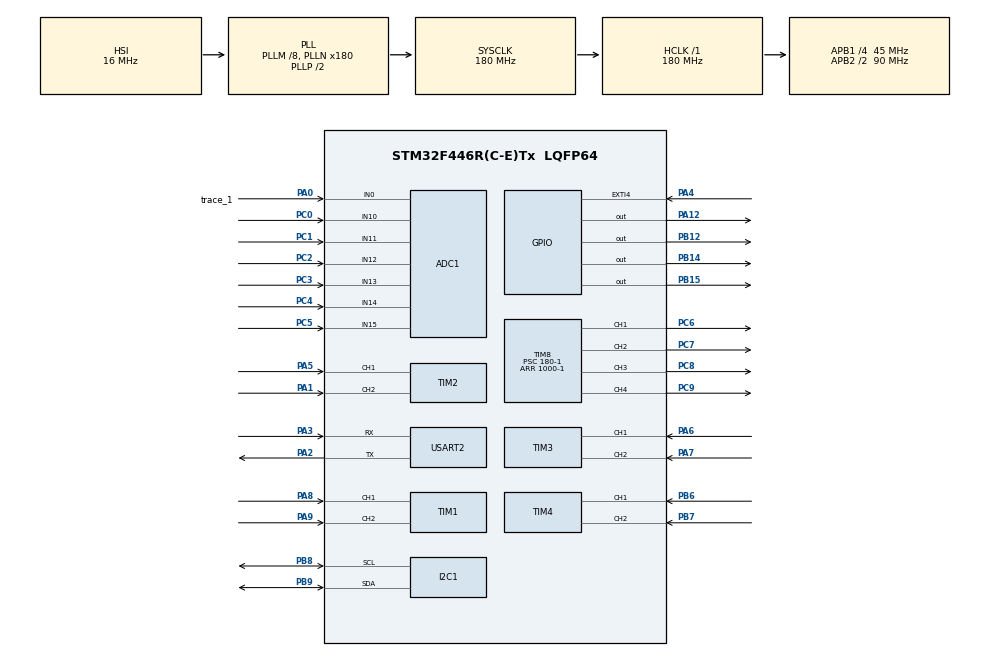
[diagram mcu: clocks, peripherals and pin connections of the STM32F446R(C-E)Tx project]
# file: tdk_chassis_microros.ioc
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ADC1.Channel-0\#ChannelRegularConversion=ADC_CHANNEL_0
ADC1.Channel-1\#ChannelRegularConversion=ADC_CHANNEL_10
ADC1.Channel-2\#ChannelRegularConversion=ADC_CHANNEL_11
ADC1.Channel-3\#ChannelRegularConversion=ADC_CHANNEL_12
ADC1.Channel-4\#ChannelRegularConversion=ADC_CHANNEL_13
ADC1.Channel-5\#ChannelRegularConversion=ADC_CHANNEL_14
ADC1.Channel-6\#ChannelRegularConversion=ADC_CHANNEL_15
ADC1.ContinuousConvMode=ENABLE
ADC1.DMAContinuousRequests=ENABLE
ADC1.DiscontinuousConvMode=DISABLE
ADC1.NbrOfConversion=7
ADC1.NbrOfConversionFlag=1
ADC1.Rank-0\#ChannelRegularConversion=1
ADC1.Rank-1\#ChannelRegularConversion=2
ADC1.Rank-2\#ChannelRegularConversion=3
ADC1.Rank-3\#ChannelRegularConversion=4
ADC1.Rank-4\#ChannelRegularConversion=5
ADC1.Rank-5\#ChannelRegularConversion=6
ADC1.Rank-6\#ChannelRegularConversion=7
ADC1.SamplingTime-0\#ChannelRegularConversion=ADC_SAMPLETIME_15CYCLES
ADC1.SamplingTime-1\#ChannelRegularConversion=ADC_SAMPLETIME_15CYCLES
ADC1.SamplingTime-2\#ChannelRegularConversion=ADC_SAMPLETIME_15CYCLES
ADC1.SamplingTime-3\#ChannelRegularConversion=ADC_SAMPLETIME_15CYCLES
ADC1.SamplingTime-4\#ChannelRegularConversion=ADC_SAMPLETIME_15CYCLES
ADC1.SamplingTime-5\#ChannelRegularConversion=ADC_SAMPLETIME_15CYCLES
ADC1.SamplingTime-6\#ChannelRegularConversion=ADC_SAMPLETIME_15CYCLES
ADC1.ScanConvMode=ENABLE
ADC1.master=1
Dma.ADC1.2.Direction=DMA_PERIPH_TO_MEMORY
Dma.ADC1.2.FIFOMode=DMA_FIFOMODE_DISABLE
Dma.ADC1.2.Instance=DMA2_Stream0
Dma.ADC1.2.MemDataAlignment=DMA_MDATAALIGN_HALFWORD
Dma.ADC1.2.MemInc=DMA_MINC_ENABLE
Dma.ADC1.2.Mode=DMA_CIRCULAR
Dma.ADC1.2.PeriphDataAlignment=DMA_PDATAALIGN_HALFWORD
Dma.ADC1.2.PeriphInc=DMA_PINC_DISABLE
Dma.ADC1.2.Priority=DMA_PRIORITY_LOW
Dma.Request0=USART2_RX
Dma.Request1=USART2_TX
Dma.Request2=ADC1
Dma.USART2_RX.0.Direction=DMA_PERIPH_TO_MEMORY
Dma.USART2_RX.0.FIFOMode=DMA_FIFOMODE_DISABLE
Dma.USART2_RX.0.Instance=DMA1_Stream5
Dma.USART2_RX.0.MemDataAlignment=DMA_MDATAALIGN_BYTE
Dma.USART2_RX.0.MemInc=DMA_MINC_ENABLE
Dma.USART2_RX.0.Mode=DMA_CIRCULAR
Dma.USART2_RX.0.PeriphDataAlignment=DMA_PDATAALIGN_BYTE
Dma.USART2_RX.0.PeriphInc=DMA_PINC_DISABLE
Dma.USART2_RX.0.Priority=DMA_PRIORITY_VERY_HIGH
Dma.USART2_TX.1.Direction=DMA_MEMORY_TO_PERIPH
Dma.USART2_TX.1.FIFOMode=DMA_FIFOMODE_DISABLE
Dma.USART2_TX.1.Instance=DMA1_Stream6
Dma.USART2_TX.1.MemDataAlignment=DMA_MDATAALIGN_BYTE
Dma.USART2_TX.1.MemInc=DMA_MINC_ENABLE
Dma.USART2_TX.1.Mode=DMA_NORMAL
Dma.USART2_TX.1.PeriphDataAlignment=DMA_PDATAALIGN_BYTE
Dma.USART2_TX.1.PeriphInc=DMA_PINC_DISABLE
Dma.USART2_TX.1.Priority=DMA_PRIORITY_VERY_HIGH
FREERTOS.Tasks01=defaultTask,24,3000,StartDefaultTask,Default,NULL,Static,defaultTaskBuffer,defaultTaskControlBlock
FREERTOS.configUSE_NEWLIB_REENTRANT=1
Mcu.Family=STM32F4
Mcu.Name=STM32F446R(C-E)Tx
Mcu.Package=LQFP64
NVIC.DMA1_Stream5_IRQn=true\:5\:0\:false\:false\:true\:true\:false\:true\:true
NVIC.DMA1_Stream6_IRQn=true\:5\:0\:false\:false\:true\:true\:false\:true\:true
NVIC.DMA2_Stream0_IRQn=true\:5\:0\:false\:false\:true\:true\:false\:true\:true
NVIC.EXTI4_IRQn=true\:5\:0\:false\:false\:true\:true\:true\:true\:true
NVIC.PriorityGroup=NVIC_PRIORITYGROUP_4
NVIC.TIM5_IRQn=true\:5\:0\:false\:false\:true\:true\:true\:true\:true
NVIC.TIM6_DAC_IRQn=true\:15\:0\:false\:false\:true\:false\:false\:true\:true
NVIC.TimeBase=TIM6_DAC_IRQn
NVIC.TimeBaseIP=TIM6
NVIC.USART2_IRQn=true\:5\:0\:false\:false\:true\:true\:true\:true\:true
PA0-WKUP.GPIO_Label=trace_1
PA0-WKUP.Signal=ADCx_IN0
PA1.Signal=S_TIM2_CH2
PA12.Signal=GPIO_Output
PA13.Mode=Serial_Wire
PA13.Signal=SYS_JTMS-SWDIO
PA14.Mode=Serial_Wire
PA14.Signal=SYS_JTCK-SWCLK
PA2.Mode=Asynchronous
PA2.Signal=USART2_TX
PA3.Mode=Asynchronous
PA3.Signal=USART2_RX
PA4.GPIO_ModeDefaultEXTI=GPIO_MODE_IT_FALLING
PA4.GPIO_PuPd=GPIO_PULLUP
PA4.Signal=GPXTI4
PA5.Signal=S_TIM2_CH1_ETR
PA6.Signal=S_TIM3_CH1
PA7.Signal=S_TIM3_CH2
PA8.Signal=S_TIM1_CH1
PA9.Signal=S_TIM1_CH2
PB12.Signal=GPIO_Output
PB14.Signal=GPIO_Output
PB15.Signal=GPIO_Output
PB6.Signal=S_TIM4_CH1
PB7.Signal=S_TIM4_CH2
PB8.Mode=I2C
PB8.Signal=I2C1_SCL
PB9.Mode=I2C
PB9.Signal=I2C1_SDA
PC0.Signal=ADCx_IN10
PC1.Signal=ADCx_IN11
PC2.Signal=ADCx_IN12
PC3.Signal=ADCx_IN13
PC4.Signal=ADCx_IN14
PC5.Signal=ADCx_IN15
PC6.Signal=S_TIM8_CH1
PC7.Signal=S_TIM8_CH2
PC8.Signal=S_TIM8_CH3
PC9.Signal=S_TIM8_CH4
ProjectManager.HeapSize=0x200
ProjectManager.StackSize=0x400
ProjectManager.TargetToolchain=STM32CubeIDE
RCC.AHBFreq_Value=180000000
RCC.APB1CLKDivider=RCC_HCLK_DIV4
RCC.APB1Freq_Value=45000000
RCC.APB1TimFreq_Value=90000000
RCC.APB2CLKDivider=RCC_HCLK_DIV2
RCC.APB2Freq_Value=90000000
RCC.APB2TimFreq_Value=180000000
RCC.CortexFreq_Value=180000000
RCC.HCLKFreq_Value=180000000
RCC.PLLM=8
RCC.PLLN=180
RCC.SYSCLKFreq_VALUE=180000000
RCC.SYSCLKSource=RCC_SYSCLKSOURCE_PLLCLK
RCC.USBFreq_Value=180000000
RCC.VCOOutputFreq_Value=360000000
SH.ADCx_IN0.0=ADC1_IN0,IN0
SH.ADCx_IN10.0=ADC1_IN10,IN10
SH.ADCx_IN11.0=ADC1_IN11,IN11
SH.ADCx_IN12.0=ADC1_IN12,IN12
SH.ADCx_IN13.0=ADC1_IN13,IN13
SH.ADCx_IN14.0=ADC1_IN14,IN14
SH.ADCx_IN15.0=ADC1_IN15,IN15
SH.S_TIM1_CH1.0=TIM1_CH1,Encoder_Interface
SH.S_TIM1_CH2.0=TIM1_CH2,Encoder_Interface
SH.S_TIM2_CH1_ETR.0=TIM2_CH1,Encoder_Interface
SH.S_TIM2_CH2.0=TIM2_CH2,Encoder_Interface
SH.S_TIM3_CH1.0=TIM3_CH1,Encoder_Interface
SH.S_TIM3_CH2.0=TIM3_CH2,Encoder_Interface
SH.S_TIM4_CH1.0=TIM4_CH1,Encoder_Interface
SH.S_TIM4_CH2.0=TIM4_CH2,Encoder_Interface
SH.S_TIM8_CH1.0=TIM8_CH1,PWM Generation1 CH1
SH.S_TIM8_CH2.0=TIM8_CH2,PWM Generation2 CH2
SH.S_TIM8_CH3.0=TIM8_CH3,PWM Generation3 CH3
SH.S_TIM8_CH4.0=TIM8_CH4,PWM Generation4 CH4
TIM1.EncoderMode=TIM_ENCODERMODE_TI12
TIM2.EncoderMode=TIM_ENCODERMODE_TI12
TIM3.EncoderMode=TIM_ENCODERMODE_TI12
TIM4.EncoderMode=TIM_ENCODERMODE_TI12
TIM5.Period=10000-1
TIM5.Prescaler=90-1
TIM8.Channel-PWM\ Generation1\ CH1=TIM_CHANNEL_1
TIM8.Channel-PWM\ Generation2\ CH2=TIM_CHANNEL_2
TIM8.Channel-PWM\ Generation3\ CH3=TIM_CHANNEL_3
TIM8.Channel-PWM\ Generation4\ CH4=TIM_CHANNEL_4
TIM8.Period=1000-1
TIM8.Prescaler=180-1
USART2.VirtualMode=VM_ASYNC
VP_FREERTOS_VS_CMSIS_V2.Mode=CMSIS_V2
VP_SYS_VS_tim6.Mode=TIM6
VP_TIM5_VS_ClockSourceINT.Mode=Internal
board=custom

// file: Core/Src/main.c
/* USER CODE BEGIN Header */
/**
  ******************************************************************************
  * @file           : main.c
  * @brief          : Main program body
  ******************************************************************************
  * @attention
  *
  * Copyright (c) 2025 STMicroelectronics.
  * All rights reserved.
  *
  * This software is licensed under terms that can be found in the LICENSE file
  * in the root directory of this software component.
  * If no LICENSE file comes with this software, it is provided AS-IS.
  *
  ******************************************************************************
  */
/* USER CODE END Header */
#include "main.h"
#include "cmsis_os.h"

typedef StaticTask_t osStaticThreadDef_t;

ADC_HandleTypeDef hadc1;
DMA_HandleTypeDef hdma_adc1;

I2C_HandleTypeDef hi2c1;

TIM_HandleTypeDef htim1;
TIM_HandleTypeDef htim2;
TIM_HandleTypeDef htim3;
TIM_HandleTypeDef htim4;
TIM_HandleTypeDef htim5;
TIM_HandleTypeDef htim8;

UART_HandleTypeDef huart2;
DMA_HandleTypeDef hdma_usart2_rx;
DMA_HandleTypeDef hdma_usart2_tx;

/* Definitions for defaultTask */
osThreadId_t defaultTaskHandle;
uint32_t defaultTaskBuffer[ 3000 ];
osStaticThreadDef_t defaultTaskControlBlock;
const osThreadAttr_t defaultTask_attributes = {
  .name = "defaultTask",
  .cb_mem = &defaultTaskControlBlock,
  .cb_size = sizeof(defaultTaskControlBlock),
  .stack_mem = &defaultTaskBuffer[0],
  .stack_size = sizeof(defaultTaskBuffer),
  .priority = (osPriority_t) osPriorityNormal,
};

void SystemClock_Config(void);
static void MX_GPIO_Init(void);
static void MX_DMA_Init(void);
static void MX_USART2_UART_Init(void);
static void MX_TIM1_Init(void);
static void MX_TIM2_Init(void);
static void MX_TIM3_Init(void);
static void MX_TIM4_Init(void);
static void MX_TIM5_Init(void);
static void MX_TIM8_Init(void);
static void MX_ADC1_Init(void);
static void MX_I2C1_Init(void);
void StartDefaultTask(void *argument);

int main(void)
{

  /* MCU Configuration--------------------------------------------------------*/

  /* Reset of all peripherals, Initializes the Flash interface and the Systick. */
  HAL_Init();

  /* Configure the system clock */
  SystemClock_Config();

  /* Initialize all configured peripherals */
  MX_GPIO_Init();
  MX_DMA_Init();
  MX_USART2_UART_Init();
  MX_TIM1_Init();
  MX_TIM2_Init();
  MX_TIM3_Init();
  MX_TIM4_Init();
  MX_TIM5_Init();
  MX_TIM8_Init();
  MX_ADC1_Init();
  MX_I2C1_Init();

  /* Init scheduler */
  osKernelInitialize();

  /* Create the thread(s) */
  /* creation of defaultTask */
  defaultTaskHandle = osThreadNew(StartDefaultTask, NULL, &defaultTask_attributes);

  /* Start scheduler */
  osKernelStart();

  /* We should never get here as control is now taken by the scheduler */

  /* Infinite loop */
  while (1)
  {

  }
}

void SystemClock_Config(void)
{
  RCC_OscInitTypeDef RCC_OscInitStruct = {0};
  RCC_ClkInitTypeDef RCC_ClkInitStruct = {0};

  /** Configure the main internal regulator output voltage
  */
  __HAL_RCC_PWR_CLK_ENABLE();
  __HAL_PWR_VOLTAGESCALING_CONFIG(PWR_REGULATOR_VOLTAGE_SCALE1);

  /** Initializes the RCC Oscillators according to the specified parameters
  * in the RCC_OscInitTypeDef structure.
  */
  RCC_OscInitStruct.OscillatorType = RCC_OSCILLATORTYPE_HSI;
  RCC_OscInitStruct.HSIState = RCC_HSI_ON;
  RCC_OscInitStruct.HSICalibrationValue = RCC_HSICALIBRATION_DEFAULT;
  RCC_OscInitStruct.PLL.PLLState = RCC_PLL_ON;
  RCC_OscInitStruct.PLL.PLLSource = RCC_PLLSOURCE_HSI;
  RCC_OscInitStruct.PLL.PLLM = 8;
  RCC_OscInitStruct.PLL.PLLN = 180;
  RCC_OscInitStruct.PLL.PLLP = RCC_PLLP_DIV2;
  RCC_OscInitStruct.PLL.PLLQ = 2;
  RCC_OscInitStruct.PLL.PLLR = 2;
  if (HAL_RCC_OscConfig(&RCC_OscInitStruct) != HAL_OK)
  {
    Error_Handler();
  }

  /** Activate the Over-Drive mode
  */
  if (HAL_PWREx_EnableOverDrive() != HAL_OK)
  {
    Error_Handler();
  }

  /** Initializes the CPU, AHB and APB buses clocks
  */
  RCC_ClkInitStruct.ClockType = RCC_CLOCKTYPE_HCLK|RCC_CLOCKTYPE_SYSCLK
                              |RCC_CLOCKTYPE_PCLK1|RCC_CLOCKTYPE_PCLK2;
  RCC_ClkInitStruct.SYSCLKSource = RCC_SYSCLKSOURCE_PLLCLK;
  RCC_ClkInitStruct.AHBCLKDivider = RCC_SYSCLK_DIV1;
  RCC_ClkInitStruct.APB1CLKDivider = RCC_HCLK_DIV4;
  RCC_ClkInitStruct.APB2CLKDivider = RCC_HCLK_DIV2;

  if (HAL_RCC_ClockConfig(&RCC_ClkInitStruct, FLASH_LATENCY_5) != HAL_OK)
  {
    Error_Handler();
  }
}

static void MX_ADC1_Init(void)
{

  ADC_ChannelConfTypeDef sConfig = {0};

  /** Configure the global features of the ADC (Clock, Resolution, Data Alignment and number of conversion)
  */
  hadc1.Instance = ADC1;
  hadc1.Init.ClockPrescaler = ADC_CLOCK_SYNC_PCLK_DIV4;
  hadc1.Init.Resolution = ADC_RESOLUTION_12B;
  hadc1.Init.ScanConvMode = ENABLE;
  hadc1.Init.ContinuousConvMode = ENABLE;
  hadc1.Init.DiscontinuousConvMode = DISABLE;
  hadc1.Init.ExternalTrigConvEdge = ADC_EXTERNALTRIGCONVEDGE_NONE;
  hadc1.Init.ExternalTrigConv = ADC_SOFTWARE_START;
  hadc1.Init.DataAlign = ADC_DATAALIGN_RIGHT;
  hadc1.Init.NbrOfConversion = 7;
  hadc1.Init.DMAContinuousRequests = ENABLE;
  hadc1.Init.EOCSelection = ADC_EOC_SINGLE_CONV;
  if (HAL_ADC_Init(&hadc1) != HAL_OK)
  {
    Error_Handler();
  }

  /** Configure for the selected ADC regular channel its corresponding rank in the sequencer and its sample time.
  */
  sConfig.Channel = ADC_CHANNEL_0;
  sConfig.Rank = 1;
  sConfig.SamplingTime = ADC_SAMPLETIME_15CYCLES;
  if (HAL_ADC_ConfigChannel(&hadc1, &sConfig) != HAL_OK)
  {
    Error_Handler();
  }

  /** Configure for the selected ADC regular channel its corresponding rank in the sequencer and its sample time.
  */
  sConfig.Channel = ADC_CHANNEL_10;
  sConfig.Rank = 2;
  if (HAL_ADC_ConfigChannel(&hadc1, &sConfig) != HAL_OK)
  {
    Error_Handler();
  }

  /** Configure for the selected ADC regular channel its corresponding rank in the sequencer and its sample time.
  */
  sConfig.Channel = ADC_CHANNEL_11;
  sConfig.Rank = 3;
  if (HAL_ADC_ConfigChannel(&hadc1, &sConfig) != HAL_OK)
  {
    Error_Handler();
  }

  /** Configure for the selected ADC regular channel its corresponding rank in the sequencer and its sample time.
  */
  sConfig.Channel = ADC_CHANNEL_12;
  sConfig.Rank = 4;
  if (HAL_ADC_ConfigChannel(&hadc1, &sConfig) != HAL_OK)
  {
    Error_Handler();
  }

  /** Configure for the selected ADC regular channel its corresponding rank in the sequencer and its sample time.
  */
  sConfig.Channel = ADC_CHANNEL_13;
  sConfig.Rank = 5;
  if (HAL_ADC_ConfigChannel(&hadc1, &sConfig) != HAL_OK)
  {
    Error_Handler();
  }

  /** Configure for the selected ADC regular channel its corresponding rank in the sequencer and its sample time.
  */
  sConfig.Channel = ADC_CHANNEL_14;
  sConfig.Rank = 6;
  if (HAL_ADC_ConfigChannel(&hadc1, &sConfig) != HAL_OK)
  {
    Error_Handler();
  }

  /** Configure for the selected ADC regular channel its corresponding rank in the sequencer and its sample time.
  */
  sConfig.Channel = ADC_CHANNEL_15;
  sConfig.Rank = 7;
  if (HAL_ADC_ConfigChannel(&hadc1, &sConfig) != HAL_OK)
  {
    Error_Handler();
  }

}

static void MX_I2C1_Init(void)
{

  hi2c1.Instance = I2C1;
  hi2c1.Init.ClockSpeed = 100000;
  hi2c1.Init.DutyCycle = I2C_DUTYCYCLE_2;
  hi2c1.Init.OwnAddress1 = 0;
  hi2c1.Init.AddressingMode = I2C_ADDRESSINGMODE_7BIT;
  hi2c1.Init.DualAddressMode = I2C_DUALADDRESS_DISABLE;
  hi2c1.Init.OwnAddress2 = 0;
  hi2c1.Init.GeneralCallMode = I2C_GENERALCALL_DISABLE;
  hi2c1.Init.NoStretchMode = I2C_NOSTRETCH_DISABLE;
  if (HAL_I2C_Init(&hi2c1) != HAL_OK)
  {
    Error_Handler();
  }

}

static void MX_TIM1_Init(void)
{

  TIM_Encoder_InitTypeDef sConfig = {0};
  TIM_MasterConfigTypeDef sMasterConfig = {0};

  htim1.Instance = TIM1;
  htim1.Init.Prescaler = 0;
  htim1.Init.CounterMode = TIM_COUNTERMODE_UP;
  htim1.Init.Period = 65535;
  htim1.Init.ClockDivision = TIM_CLOCKDIVISION_DIV1;
  htim1.Init.RepetitionCounter = 0;
  htim1.Init.AutoReloadPreload = TIM_AUTORELOAD_PRELOAD_DISABLE;
  sConfig.EncoderMode = TIM_ENCODERMODE_TI12;
  sConfig.IC1Polarity = TIM_ICPOLARITY_RISING;
  sConfig.IC1Selection = TIM_ICSELECTION_DIRECTTI;
  sConfig.IC1Prescaler = TIM_ICPSC_DIV1;
  sConfig.IC1Filter = 0;
  sConfig.IC2Polarity = TIM_ICPOLARITY_RISING;
  sConfig.IC2Selection = TIM_ICSELECTION_DIRECTTI;
  sConfig.IC2Prescaler = TIM_ICPSC_DIV1;
  sConfig.IC2Filter = 0;
  if (HAL_TIM_Encoder_Init(&htim1, &sConfig) != HAL_OK)
  {
    Error_Handler();
  }
  sMasterConfig.MasterOutputTrigger = TIM_TRGO_RESET;
  sMasterConfig.MasterSlaveMode = TIM_MASTERSLAVEMODE_DISABLE;
  if (HAL_TIMEx_MasterConfigSynchronization(&htim1, &sMasterConfig) != HAL_OK)
  {
    Error_Handler();
  }

}

static void MX_TIM2_Init(void)
{

  TIM_Encoder_InitTypeDef sConfig = {0};
  TIM_MasterConfigTypeDef sMasterConfig = {0};

  htim2.Instance = TIM2;
  htim2.Init.Prescaler = 0;
  htim2.Init.CounterMode = TIM_COUNTERMODE_UP;
  htim2.Init.Period = 4294967295;
  htim2.Init.ClockDivision = TIM_CLOCKDIVISION_DIV1;
  htim2.Init.AutoReloadPreload = TIM_AUTORELOAD_PRELOAD_DISABLE;
  sConfig.EncoderMode = TIM_ENCODERMODE_TI12;
  sConfig.IC1Polarity = TIM_ICPOLARITY_RISING;
  sConfig.IC1Selection = TIM_ICSELECTION_DIRECTTI;
  sConfig.IC1Prescaler = TIM_ICPSC_DIV1;
  sConfig.IC1Filter = 0;
  sConfig.IC2Polarity = TIM_ICPOLARITY_RISING;
  sConfig.IC2Selection = TIM_ICSELECTION_DIRECTTI;
  sConfig.IC2Prescaler = TIM_ICPSC_DIV1;
  sConfig.IC2Filter = 0;
  if (HAL_TIM_Encoder_Init(&htim2, &sConfig) != HAL_OK)
  {
    Error_Handler();
  }
  sMasterConfig.MasterOutputTrigger = TIM_TRGO_RESET;
  sMasterConfig.MasterSlaveMode = TIM_MASTERSLAVEMODE_DISABLE;
  if (HAL_TIMEx_MasterConfigSynchronization(&htim2, &sMasterConfig) != HAL_OK)
  {
    Error_Handler();
  }

}

static void MX_TIM3_Init(void)
{

  TIM_Encoder_InitTypeDef sConfig = {0};
  TIM_MasterConfigTypeDef sMasterConfig = {0};

  htim3.Instance = TIM3;
  htim3.Init.Prescaler = 0;
  htim3.Init.CounterMode = TIM_COUNTERMODE_UP;
  htim3.Init.Period = 65535;
  htim3.Init.ClockDivision = TIM_CLOCKDIVISION_DIV1;
  htim3.Init.AutoReloadPreload = TIM_AUTORELOAD_PRELOAD_DISABLE;
  sConfig.EncoderMode = TIM_ENCODERMODE_TI12;
  sConfig.IC1Polarity = TIM_ICPOLARITY_RISING;
  sConfig.IC1Selection = TIM_ICSELECTION_DIRECTTI;
  sConfig.IC1Prescaler = TIM_ICPSC_DIV1;
  sConfig.IC1Filter = 0;
  sConfig.IC2Polarity = TIM_ICPOLARITY_RISING;
  sConfig.IC2Selection = TIM_ICSELECTION_DIRECTTI;
  sConfig.IC2Prescaler = TIM_ICPSC_DIV1;
  sConfig.IC2Filter = 0;
  if (HAL_TIM_Encoder_Init(&htim3, &sConfig) != HAL_OK)
  {
    Error_Handler();
  }
  sMasterConfig.MasterOutputTrigger = TIM_TRGO_RESET;
  sMasterConfig.MasterSlaveMode = TIM_MASTERSLAVEMODE_DISABLE;
  if (HAL_TIMEx_MasterConfigSynchronization(&htim3, &sMasterConfig) != HAL_OK)
  {
    Error_Handler();
  }

}

static void MX_TIM4_Init(void)
{

  TIM_Encoder_InitTypeDef sConfig = {0};
  TIM_MasterConfigTypeDef sMasterConfig = {0};

  htim4.Instance = TIM4;
  htim4.Init.Prescaler = 0;
  htim4.Init.CounterMode = TIM_COUNTERMODE_UP;
  htim4.Init.Period = 65535;
  htim4.Init.ClockDivision = TIM_CLOCKDIVISION_DIV1;
  htim4.Init.AutoReloadPreload = TIM_AUTORELOAD_PRELOAD_DISABLE;
  sConfig.EncoderMode = TIM_ENCODERMODE_TI12;
  sConfig.IC1Polarity = TIM_ICPOLARITY_RISING;
  sConfig.IC1Selection = TIM_ICSELECTION_DIRECTTI;
  sConfig.IC1Prescaler = TIM_ICPSC_DIV1;
  sConfig.IC1Filter = 0;
  sConfig.IC2Polarity = TIM_ICPOLARITY_RISING;
  sConfig.IC2Selection = TIM_ICSELECTION_DIRECTTI;
  sConfig.IC2Prescaler = TIM_ICPSC_DIV1;
  sConfig.IC2Filter = 0;
  if (HAL_TIM_Encoder_Init(&htim4, &sConfig) != HAL_OK)
  {
    Error_Handler();
  }
  sMasterConfig.MasterOutputTrigger = TIM_TRGO_RESET;
  sMasterConfig.MasterSlaveMode = TIM_MASTERSLAVEMODE_DISABLE;
  if (HAL_TIMEx_MasterConfigSynchronization(&htim4, &sMasterConfig) != HAL_OK)
  {
    Error_Handler();
  }

}

static void MX_TIM5_Init(void)
{

  TIM_ClockConfigTypeDef sClockSourceConfig = {0};
  TIM_MasterConfigTypeDef sMasterConfig = {0};

  htim5.Instance = TIM5;
  htim5.Init.Prescaler = 90-1;
  htim5.Init.CounterMode = TIM_COUNTERMODE_UP;
  htim5.Init.Period = 10000-1;
  htim5.Init.ClockDivision = TIM_CLOCKDIVISION_DIV1;
  htim5.Init.AutoReloadPreload = TIM_AUTORELOAD_PRELOAD_DISABLE;
  if (HAL_TIM_Base_Init(&htim5) != HAL_OK)
  {
    Error_Handler();
  }
  sClockSourceConfig.ClockSource = TIM_CLOCKSOURCE_INTERNAL;
  if (HAL_TIM_ConfigClockSource(&htim5, &sClockSourceConfig) != HAL_OK)
  {
    Error_Handler();
  }
  sMasterConfig.MasterOutputTrigger = TIM_TRGO_RESET;
  sMasterConfig.MasterSlaveMode = TIM_MASTERSLAVEMODE_DISABLE;
  if (HAL_TIMEx_MasterConfigSynchronization(&htim5, &sMasterConfig) != HAL_OK)
  {
    Error_Handler();
  }

}

static void MX_TIM8_Init(void)
{

  TIM_MasterConfigTypeDef sMasterConfig = {0};
  TIM_OC_InitTypeDef sConfigOC = {0};
  TIM_BreakDeadTimeConfigTypeDef sBreakDeadTimeConfig = {0};

  htim8.Instance = TIM8;
  htim8.Init.Prescaler = 180-1;
  htim8.Init.CounterMode = TIM_COUNTERMODE_UP;
  htim8.Init.Period = 1000-1;
  htim8.Init.ClockDivision = TIM_CLOCKDIVISION_DIV1;
  htim8.Init.RepetitionCounter = 0;
  htim8.Init.AutoReloadPreload = TIM_AUTORELOAD_PRELOAD_DISABLE;
  if (HAL_TIM_PWM_Init(&htim8) != HAL_OK)
  {
    Error_Handler();
  }
  sMasterConfig.MasterOutputTrigger = TIM_TRGO_RESET;
  sMasterConfig.MasterSlaveMode = TIM_MASTERSLAVEMODE_DISABLE;
  if (HAL_TIMEx_MasterConfigSynchronization(&htim8, &sMasterConfig) != HAL_OK)
  {
    Error_Handler();
  }
  sConfigOC.OCMode = TIM_OCMODE_PWM1;
  sConfigOC.Pulse = 0;
  sConfigOC.OCPolarity = TIM_OCPOLARITY_HIGH;
  sConfigOC.OCNPolarity = TIM_OCNPOLARITY_HIGH;
  sConfigOC.OCFastMode = TIM_OCFAST_DISABLE;
  sConfigOC.OCIdleState = TIM_OCIDLESTATE_RESET;
  sConfigOC.OCNIdleState = TIM_OCNIDLESTATE_RESET;
  if (HAL_TIM_PWM_ConfigChannel(&htim8, &sConfigOC, TIM_CHANNEL_1) != HAL_OK)
  {
    Error_Handler();
  }
  if (HAL_TIM_PWM_ConfigChannel(&htim8, &sConfigOC, TIM_CHANNEL_2) != HAL_OK)
  {
    Error_Handler();
  }
  if (HAL_TIM_PWM_ConfigChannel(&htim8, &sConfigOC, TIM_CHANNEL_3) != HAL_OK)
  {
    Error_Handler();
  }
  if (HAL_TIM_PWM_ConfigChannel(&htim8, &sConfigOC, TIM_CHANNEL_4) != HAL_OK)
  {
    Error_Handler();
  }
  sBreakDeadTimeConfig.OffStateRunMode = TIM_OSSR_DISABLE;
  sBreakDeadTimeConfig.OffStateIDLEMode = TIM_OSSI_DISABLE;
  sBreakDeadTimeConfig.LockLevel = TIM_LOCKLEVEL_OFF;
  sBreakDeadTimeConfig.DeadTime = 0;
  sBreakDeadTimeConfig.BreakState = TIM_BREAK_DISABLE;
  sBreakDeadTimeConfig.BreakPolarity = TIM_BREAKPOLARITY_HIGH;
  sBreakDeadTimeConfig.AutomaticOutput = TIM_AUTOMATICOUTPUT_DISABLE;
  if (HAL_TIMEx_ConfigBreakDeadTime(&htim8, &sBreakDeadTimeConfig) != HAL_OK)
  {
    Error_Handler();
  }
  HAL_TIM_MspPostInit(&htim8);

}

static void MX_USART2_UART_Init(void)
{

  huart2.Instance = USART2;
  huart2.Init.BaudRate = 115200;
  huart2.Init.WordLength = UART_WORDLENGTH_8B;
  huart2.Init.StopBits = UART_STOPBITS_1;
  huart2.Init.Parity = UART_PARITY_NONE;
  huart2.Init.Mode = UART_MODE_TX_RX;
  huart2.Init.HwFlowCtl = UART_HWCONTROL_NONE;
  huart2.Init.OverSampling = UART_OVERSAMPLING_16;
  if (HAL_UART_Init(&huart2) != HAL_OK)
  {
    Error_Handler();
  }

}

static void MX_DMA_Init(void)
{

  /* DMA controller clock enable */
  __HAL_RCC_DMA1_CLK_ENABLE();
  __HAL_RCC_DMA2_CLK_ENABLE();

  /* DMA interrupt init */
  /* DMA1_Stream5_IRQn interrupt configuration */
  HAL_NVIC_SetPriority(DMA1_Stream5_IRQn, 5, 0);
  HAL_NVIC_EnableIRQ(DMA1_Stream5_IRQn);
  /* DMA1_Stream6_IRQn interrupt configuration */
  HAL_NVIC_SetPriority(DMA1_Stream6_IRQn, 5, 0);
  HAL_NVIC_EnableIRQ(DMA1_Stream6_IRQn);
  /* DMA2_Stream0_IRQn interrupt configuration */
  HAL_NVIC_SetPriority(DMA2_Stream0_IRQn, 5, 0);
  HAL_NVIC_EnableIRQ(DMA2_Stream0_IRQn);

}

static void MX_GPIO_Init(void)
{
  GPIO_InitTypeDef GPIO_InitStruct = {0};

  /* GPIO Ports Clock Enable */
  __HAL_RCC_GPIOC_CLK_ENABLE();
  __HAL_RCC_GPIOA_CLK_ENABLE();
  __HAL_RCC_GPIOB_CLK_ENABLE();

  /*Configure GPIO pin Output Level */
  HAL_GPIO_WritePin(GPIOB, GPIO_PIN_12|GPIO_PIN_14|GPIO_PIN_15, GPIO_PIN_RESET);

  /*Configure GPIO pin Output Level */
  HAL_GPIO_WritePin(GPIOA, GPIO_PIN_12, GPIO_PIN_RESET);

  /*Configure GPIO pin : PA4 */
  GPIO_InitStruct.Pin = GPIO_PIN_4;
  GPIO_InitStruct.Mode = GPIO_MODE_IT_FALLING;
  GPIO_InitStruct.Pull = GPIO_PULLUP;
  HAL_GPIO_Init(GPIOA, &GPIO_InitStruct);

  /*Configure GPIO pins : PB12 PB14 PB15 */
  GPIO_InitStruct.Pin = GPIO_PIN_12|GPIO_PIN_14|GPIO_PIN_15;
  GPIO_InitStruct.Mode = GPIO_MODE_OUTPUT_PP;
  GPIO_InitStruct.Pull = GPIO_NOPULL;
  GPIO_InitStruct.Speed = GPIO_SPEED_FREQ_LOW;
  HAL_GPIO_Init(GPIOB, &GPIO_InitStruct);

  /*Configure GPIO pin : PA12 */
  GPIO_InitStruct.Pin = GPIO_PIN_12;
  GPIO_InitStruct.Mode = GPIO_MODE_OUTPUT_PP;
  GPIO_InitStruct.Pull = GPIO_NOPULL;
  GPIO_InitStruct.Speed = GPIO_SPEED_FREQ_LOW;
  HAL_GPIO_Init(GPIOA, &GPIO_InitStruct);

  /* EXTI interrupt init*/
  HAL_NVIC_SetPriority(EXTI4_IRQn, 5, 0);
  HAL_NVIC_EnableIRQ(EXTI4_IRQn);

}

__weak void StartDefaultTask(void *argument)
{
  /* USER CODE BEGIN 5 */
//  /* Infinite loop */
//  for(;;)
//  {
//    osDelay(1);
//  }
  /* USER CODE END 5 */
}

__weak void HAL_TIM_PeriodElapsedCallback(TIM_HandleTypeDef *htim)
{
  if (htim->Instance == TIM6)
  {
    HAL_IncTick();
  }
}

void Error_Handler(void)
{
  __disable_irq();
  while (1)
  {
  }
}
